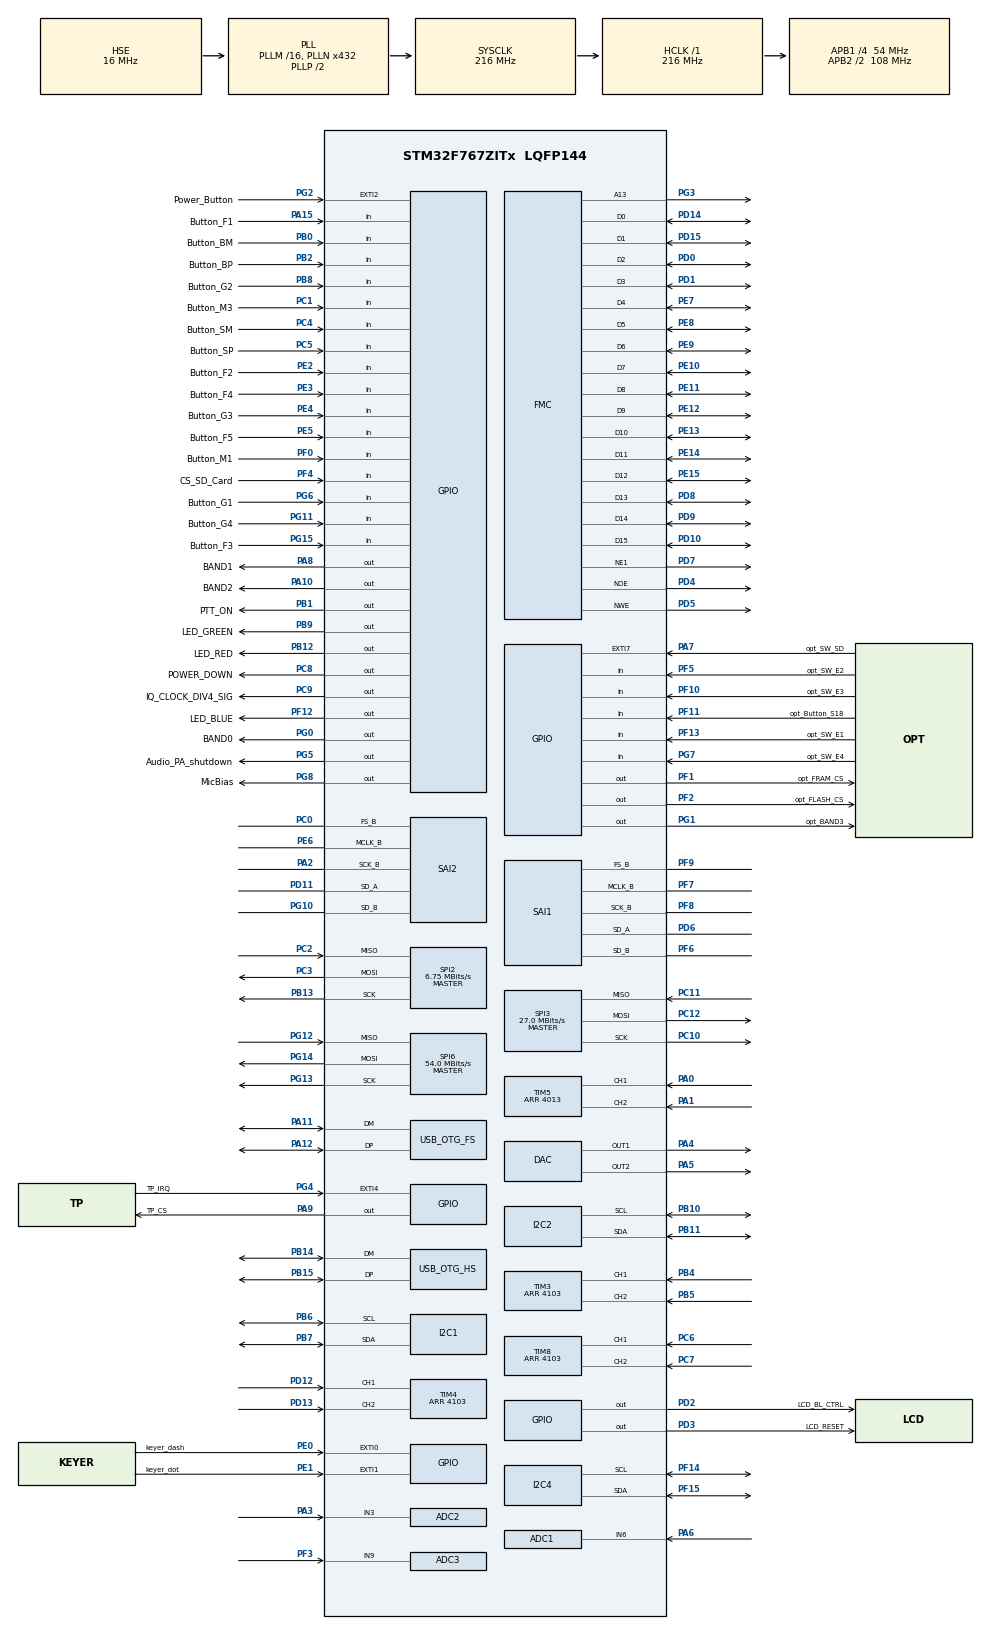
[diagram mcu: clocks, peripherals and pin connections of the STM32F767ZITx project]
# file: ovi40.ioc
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ADC1.Channel-0\#ChannelRegularConversion=ADC_CHANNEL_6
ADC1.ClockPrescaler=ADC_CLOCK_SYNC_PCLK_DIV8
ADC1.ContinuousConvMode=ENABLE
ADC1.EOCSelection=ADC_EOC_SEQ_CONV
ADC1.NbrOfConversionFlag=1
ADC1.Rank-0\#ChannelRegularConversion=1
ADC1.SamplingTime-0\#ChannelRegularConversion=ADC_SAMPLETIME_3CYCLES
ADC1.master=1
ADC2.Channel-0\#ChannelRegularConversion=ADC_CHANNEL_3
ADC2.ClockPrescaler=ADC_CLOCK_SYNC_PCLK_DIV8
ADC2.ContinuousConvMode=ENABLE
ADC2.EOCSelection=ADC_EOC_SEQ_CONV
ADC2.NbrOfConversionFlag=1
ADC2.Rank-0\#ChannelRegularConversion=1
ADC2.SamplingTime-0\#ChannelRegularConversion=ADC_SAMPLETIME_3CYCLES
ADC3.Channel-0\#ChannelRegularConversion=ADC_CHANNEL_9
ADC3.ClockPrescaler=ADC_CLOCK_SYNC_PCLK_DIV8
ADC3.ContinuousConvMode=ENABLE
ADC3.EOCSelection=ADC_EOC_SEQ_CONV
ADC3.NbrOfConversionFlag=1
ADC3.Rank-0\#ChannelRegularConversion=1
ADC3.SamplingTime-0\#ChannelRegularConversion=ADC_SAMPLETIME_3CYCLES
CORTEX_M7.AccessPermission-Cortex_Memory_Protection_Unit_Region0_Settings=MPU_REGION_FULL_ACCESS
CORTEX_M7.BaseAddress-Cortex_Memory_Protection_Unit_Region0_Settings=0x60000000
CORTEX_M7.CPU_DCache=Enabled
CORTEX_M7.CPU_ICache=Enabled
CORTEX_M7.DisableExec-Cortex_Memory_Protection_Unit_Region0_Settings=MPU_INSTRUCTION_ACCESS_DISABLE
CORTEX_M7.Enable-Cortex_Memory_Protection_Unit_Region0_Settings=MPU_REGION_ENABLE
CORTEX_M7.IsShareable-Cortex_Memory_Protection_Unit_Region0_Settings=MPU_ACCESS_SHAREABLE
CORTEX_M7.MPU_Control=MPU_PRIVILEGED_DEFAULT
CORTEX_M7.PREFETCH_ENABLE=0
CORTEX_M7.Size-Cortex_Memory_Protection_Unit_Region0_Settings=MPU_REGION_SIZE_4MB
Dma.Request0=SAI1_A
Dma.Request1=SAI1_B
Dma.Request2=SAI2_A
Dma.Request3=SAI2_B
Dma.Request4=SPI2_TX
Dma.SAI1_A.0.Direction=DMA_PERIPH_TO_MEMORY
Dma.SAI1_A.0.FIFOMode=DMA_FIFOMODE_ENABLE
Dma.SAI1_A.0.FIFOThreshold=DMA_FIFO_THRESHOLD_FULL
Dma.SAI1_A.0.Instance=DMA2_Stream1
Dma.SAI1_A.0.MemBurst=DMA_MBURST_SINGLE
Dma.SAI1_A.0.MemDataAlignment=DMA_MDATAALIGN_HALFWORD
Dma.SAI1_A.0.MemInc=DMA_MINC_ENABLE
Dma.SAI1_A.0.Mode=DMA_CIRCULAR
Dma.SAI1_A.0.PeriphBurst=DMA_PBURST_SINGLE
Dma.SAI1_A.0.PeriphDataAlignment=DMA_PDATAALIGN_HALFWORD
Dma.SAI1_A.0.PeriphInc=DMA_PINC_DISABLE
Dma.SAI1_A.0.Priority=DMA_PRIORITY_HIGH
Dma.SAI1_B.1.Direction=DMA_MEMORY_TO_PERIPH
Dma.SAI1_B.1.FIFOMode=DMA_FIFOMODE_ENABLE
Dma.SAI1_B.1.FIFOThreshold=DMA_FIFO_THRESHOLD_FULL
Dma.SAI1_B.1.Instance=DMA2_Stream0
Dma.SAI1_B.1.MemBurst=DMA_MBURST_SINGLE
Dma.SAI1_B.1.MemDataAlignment=DMA_MDATAALIGN_HALFWORD
Dma.SAI1_B.1.MemInc=DMA_MINC_ENABLE
Dma.SAI1_B.1.Mode=DMA_CIRCULAR
Dma.SAI1_B.1.PeriphBurst=DMA_PBURST_SINGLE
Dma.SAI1_B.1.PeriphDataAlignment=DMA_PDATAALIGN_HALFWORD
Dma.SAI1_B.1.PeriphInc=DMA_PINC_DISABLE
Dma.SAI1_B.1.Priority=DMA_PRIORITY_HIGH
Dma.SAI2_A.2.Direction=DMA_PERIPH_TO_MEMORY
Dma.SAI2_A.2.FIFOMode=DMA_FIFOMODE_ENABLE
Dma.SAI2_A.2.FIFOThreshold=DMA_FIFO_THRESHOLD_FULL
Dma.SAI2_A.2.Instance=DMA2_Stream2
Dma.SAI2_A.2.MemBurst=DMA_MBURST_SINGLE
Dma.SAI2_A.2.MemDataAlignment=DMA_MDATAALIGN_HALFWORD
Dma.SAI2_A.2.MemInc=DMA_MINC_ENABLE
Dma.SAI2_A.2.Mode=DMA_CIRCULAR
Dma.SAI2_A.2.PeriphBurst=DMA_PBURST_SINGLE
Dma.SAI2_A.2.PeriphDataAlignment=DMA_PDATAALIGN_HALFWORD
Dma.SAI2_A.2.PeriphInc=DMA_PINC_DISABLE
Dma.SAI2_A.2.Priority=DMA_PRIORITY_LOW
Dma.SAI2_B.3.Direction=DMA_MEMORY_TO_PERIPH
Dma.SAI2_B.3.FIFOMode=DMA_FIFOMODE_ENABLE
Dma.SAI2_B.3.FIFOThreshold=DMA_FIFO_THRESHOLD_FULL
Dma.SAI2_B.3.Instance=DMA2_Stream6
Dma.SAI2_B.3.MemBurst=DMA_MBURST_SINGLE
Dma.SAI2_B.3.MemDataAlignment=DMA_MDATAALIGN_HALFWORD
Dma.SAI2_B.3.MemInc=DMA_MINC_ENABLE
Dma.SAI2_B.3.Mode=DMA_CIRCULAR
Dma.SAI2_B.3.PeriphBurst=DMA_PBURST_SINGLE
Dma.SAI2_B.3.PeriphDataAlignment=DMA_PDATAALIGN_HALFWORD
Dma.SAI2_B.3.PeriphInc=DMA_PINC_DISABLE
Dma.SAI2_B.3.Priority=DMA_PRIORITY_LOW
Dma.SPI2_TX.4.Direction=DMA_MEMORY_TO_PERIPH
Dma.SPI2_TX.4.FIFOMode=DMA_FIFOMODE_DISABLE
Dma.SPI2_TX.4.Instance=DMA1_Stream4
Dma.SPI2_TX.4.MemDataAlignment=DMA_MDATAALIGN_BYTE
Dma.SPI2_TX.4.MemInc=DMA_MINC_ENABLE
Dma.SPI2_TX.4.Mode=DMA_NORMAL
Dma.SPI2_TX.4.PeriphDataAlignment=DMA_PDATAALIGN_BYTE
Dma.SPI2_TX.4.PeriphInc=DMA_PINC_DISABLE
Dma.SPI2_TX.4.Priority=DMA_PRIORITY_LOW
FMC.DataSetupTime1=15
FMC.WriteFifo1=FMC_WRITE_FIFO_DISABLE
FMC.WriteFifo2=FMC_WRITE_FIFO_DISABLE
FMC.WriteFifo3=FMC_WRITE_FIFO_DISABLE
FMC.WriteFifo4=FMC_WRITE_FIFO_DISABLE
I2C2.Timing=0x20404768
I2C4.Timing=0x20404768
Mcu.Family=STM32F7
Mcu.Name=STM32F767ZITx
Mcu.Package=LQFP144
NVIC.DMA1_Stream4_IRQn=true\:0\:0\:false\:false\:true\:false
NVIC.DMA2_Stream0_IRQn=true\:0\:0\:false\:false\:true\:true
NVIC.DMA2_Stream1_IRQn=true\:0\:0\:false\:false\:true\:true
NVIC.DMA2_Stream2_IRQn=true\:0\:0\:false\:false\:true\:true
NVIC.DMA2_Stream6_IRQn=true\:0\:0\:false\:false\:true\:true
NVIC.EXTI0_IRQn=true\:14\:0\:true\:false\:true\:true
NVIC.EXTI1_IRQn=true\:14\:0\:true\:false\:true\:true
NVIC.OTG_FS_IRQn=true\:1\:0\:true\:false\:true\:true
NVIC.OTG_HS_IRQn=true\:14\:0\:true\:false\:true\:true
NVIC.PriorityGroup=NVIC_PRIORITYGROUP_4
PA0/WKUP.GPIO_PuPd=GPIO_PULLUP
PA0/WKUP.Signal=S_TIM5_CH1
PA1.GPIO_PuPd=GPIO_PULLUP
PA1.Signal=S_TIM5_CH2
PA10.GPIO_Label=BAND2
PA10.PinState=GPIO_PIN_RESET
PA10.Signal=GPIO_Output
PA11.Mode=Device_Only
PA11.Signal=USB_OTG_FS_DM
PA12.Mode=Device_Only
PA12.Signal=USB_OTG_FS_DP
PA13.Mode=Serial_Wire
PA13.Signal=SYS_JTMS-SWDIO
PA14.Mode=Serial_Wire
PA14.Signal=SYS_JTCK-SWCLK
PA15.GPIO_Label=Button_F1
PA15.GPIO_PuPd=GPIO_PULLUP
PA15.Signal=GPIO_Input
PA2.Mode=SAI_B_MasterWithClock
PA2.Signal=SAI2_SCK_B
PA3.Signal=ADCx_IN3
PA4.Signal=COMP_DAC1_group
PA5.Signal=COMP_DAC2_group
PA6.Signal=ADCx_IN6
PA7.GPIO_Label=opt_SW_SD
PA7.GPIO_PuPd=GPIO_PULLUP
PA7.Signal=GPXTI7
PA8.GPIO_Label=BAND1
PA8.Signal=GPIO_Output
PA9.GPIO_Label=TP_CS
PA9.GPIO_Speed=GPIO_SPEED_FREQ_HIGH
PA9.PinState=GPIO_PIN_SET
PA9.Signal=GPIO_Output
PB0.GPIO_Label=Button_BM
PB0.GPIO_PuPd=GPIO_PULLUP
PB0.Signal=GPIO_Input
PB1.GPIO_Label=PTT_ON
PB1.Signal=GPIO_Output
PB10.Mode=I2C
PB10.Signal=I2C2_SCL
PB11.Mode=I2C
PB11.Signal=I2C2_SDA
PB12.GPIO_Label=LED_RED
PB12.Signal=GPIO_Output
PB13.Mode=Full_Duplex_Master
PB13.Signal=SPI2_SCK
PB14.Mode=Host_FS
PB14.Signal=USB_OTG_HS_DM
PB15.Mode=Host_FS
PB15.Signal=USB_OTG_HS_DP
PB2.GPIO_Label=Button_BP
PB2.GPIO_PuPd=GPIO_PULLUP
PB2.Signal=GPIO_Input
PB4.GPIO_PuPd=GPIO_PULLUP
PB4.Signal=S_TIM3_CH1
PB5.GPIO_PuPd=GPIO_PULLUP
PB5.Signal=S_TIM3_CH2
PB6.Mode=I2C
PB6.Signal=I2C1_SCL
PB7.Mode=I2C
PB7.Signal=I2C1_SDA
PB8.GPIO_Label=Button_G2
PB8.GPIO_PuPd=GPIO_PULLUP
PB8.Signal=GPIO_Input
PB9.GPIO_Label=LED_GREEN
PB9.Signal=GPIO_Output
PC0.Mode=SAI_B_MasterWithClock
PC0.Signal=SAI2_FS_B
PC1.GPIO_Label=Button_M3
PC1.GPIO_PuPd=GPIO_PULLUP
PC1.Signal=GPIO_Input
PC10.Mode=Full_Duplex_Master
PC10.Signal=SPI3_SCK
PC11.Mode=Full_Duplex_Master
PC11.Signal=SPI3_MISO
PC12.Mode=Full_Duplex_Master
PC12.Signal=SPI3_MOSI
PC14/OSC32_IN.Mode=LSE-External-Oscillator
PC14/OSC32_IN.Signal=RCC_OSC32_IN
PC15/OSC32_OUT.Mode=LSE-External-Oscillator
PC15/OSC32_OUT.Signal=RCC_OSC32_OUT
PC2.Mode=Full_Duplex_Master
PC2.Signal=SPI2_MISO
PC3.Mode=Full_Duplex_Master
PC3.Signal=SPI2_MOSI
PC4.GPIO_Label=Button_SM
PC4.GPIO_PuPd=GPIO_PULLUP
PC4.Signal=GPIO_Input
PC5.GPIO_Label=Button_SP
PC5.GPIO_PuPd=GPIO_PULLUP
PC5.Signal=GPIO_Input
PC6.GPIO_PuPd=GPIO_PULLUP
PC6.Signal=S_TIM8_CH1
PC7.GPIO_PuPd=GPIO_PULLUP
PC7.Signal=S_TIM8_CH2
PC8.GPIO_Label=POWER_DOWN
PC8.Signal=GPIO_Output
PC9.GPIO_Label=IQ_CLOCK_DIV4_SIG
PC9.Signal=GPIO_Output
PD0.Signal=FMC_D2_DA2
PD1.Signal=FMC_D3_DA3
PD10.Signal=FMC_D15_DA15
PD11.Mode=SAI_A_SyncSlave
PD11.Signal=SAI2_SD_A
PD12.GPIO_PuPd=GPIO_PULLUP
PD12.Signal=S_TIM4_CH1
PD13.GPIO_PuPd=GPIO_PULLUP
PD13.Signal=S_TIM4_CH2
PD14.Signal=FMC_D0_DA0
PD15.Signal=FMC_D1_DA1
PD2.GPIO_Label=LCD_BL_CTRL
PD2.Signal=GPIO_Output
PD3.GPIO_Label=LCD_RESET
PD3.PinState=GPIO_PIN_SET
PD3.Signal=GPIO_Output
PD4.Signal=FMC_NOE
PD5.Signal=FMC_NWE
PD6.Mode=SAI_A_SyncSlave
PD6.Signal=SAI1_SD_A
PD7.Mode=NorPsramChipSelect1_1
PD7.Signal=FMC_NE1
PD8.Signal=FMC_D13_DA13
PD9.Signal=FMC_D14_DA14
PE0.GPIO_Label=keyer_dash
PE0.GPIO_ModeDefaultEXTI=GPIO_MODE_IT_FALLING
PE0.GPIO_PuPd=GPIO_PULLUP
PE0.Signal=GPXTI0
PE1.GPIO_Label=keyer_dot
PE1.GPIO_ModeDefaultEXTI=GPIO_MODE_IT_FALLING
PE1.GPIO_PuPd=GPIO_PULLUP
PE1.Signal=GPXTI1
PE10.Signal=FMC_D7_DA7
PE11.Signal=FMC_D8_DA8
PE12.Signal=FMC_D9_DA9
PE13.Signal=FMC_D10_DA10
PE14.Signal=FMC_D11_DA11
PE15.Signal=FMC_D12_DA12
PE2.GPIO_Label=Button_F2
PE2.GPIO_PuPd=GPIO_PULLUP
PE2.Signal=GPIO_Input
PE3.GPIO_Label=Button_F4
PE3.GPIO_PuPd=GPIO_PULLUP
PE3.Signal=GPIO_Input
PE4.GPIO_Label=Button_G3
PE4.GPIO_PuPd=GPIO_PULLUP
PE4.Signal=GPIO_Input
PE5.GPIO_Label=Button_F5
PE5.GPIO_PuPd=GPIO_PULLUP
PE5.Signal=GPIO_Input
PE6.Mode=SAI_B_MasterWithClock
PE6.Signal=SAI2_MCLK_B
PE7.Signal=FMC_D4_DA4
PE8.Signal=FMC_D5_DA5
PE9.Signal=FMC_D6_DA6
PF0.GPIO_Label=Button_M1
PF0.GPIO_PuPd=GPIO_PULLUP
PF0.Signal=GPIO_Input
PF1.GPIO_Label=opt_FRAM_CS
PF1.Signal=GPIO_Output
PF10.GPIO_Label=opt_SW_E3
PF10.GPIO_PuPd=GPIO_PULLUP
PF10.Signal=GPIO_Input
PF11.GPIO_Label=opt_Button_S18
PF11.GPIO_PuPd=GPIO_PULLUP
PF11.Signal=GPIO_Input
PF12.GPIO_Label=LED_BLUE
PF12.Signal=GPIO_Output
PF13.GPIO_Label=opt_SW_E1
PF13.GPIO_PuPd=GPIO_PULLUP
PF13.Signal=GPIO_Input
PF14.Mode=I2C
PF14.Signal=I2C4_SCL
PF15.Mode=I2C
PF15.Signal=I2C4_SDA
PF2.GPIO_Label=opt_FLASH_CS
PF2.Signal=GPIO_Output
PF3.Mode=IN9
PF3.Signal=ADC3_IN9
PF4.GPIO_Label=CS_SD_Card
PF4.GPIO_PuPd=GPIO_PULLUP
PF4.Signal=GPIO_Input
PF5.GPIO_Label=opt_SW_E2
PF5.GPIO_PuPd=GPIO_PULLUP
PF5.Signal=GPIO_Input
PF6.Mode=SAI_B_MasterWithClock
PF6.Signal=SAI1_SD_B
PF7.Mode=SAI_B_MasterWithClock
PF7.Signal=SAI1_MCLK_B
PF8.Mode=SAI_B_MasterWithClock
PF8.Signal=SAI1_SCK_B
PF9.Mode=SAI_B_MasterWithClock
PF9.Signal=SAI1_FS_B
PG0.GPIO_Label=BAND0
PG0.Signal=GPIO_Output
PG1.GPIO_Label=opt_BAND3
PG1.Signal=GPIO_Output
PG10.Mode=SAI_B_MasterWithClock
PG10.Signal=SAI2_SD_B
PG11.GPIO_Label=Button_G4
PG11.GPIO_PuPd=GPIO_PULLUP
PG11.Signal=GPIO_Input
PG12.Mode=Full_Duplex_Master
PG12.Signal=SPI6_MISO
PG13.Mode=Full_Duplex_Master
PG13.Signal=SPI6_SCK
PG14.Mode=Full_Duplex_Master
PG14.Signal=SPI6_MOSI
PG15.GPIO_Label=Button_F3
PG15.GPIO_PuPd=GPIO_PULLUP
PG15.Signal=GPIO_Input
PG2.GPIO_Label=Power_Button
PG2.GPIO_ModeDefaultEXTI=GPIO_MODE_IT_FALLING
PG2.GPIO_PuPd=GPIO_PULLUP
PG2.Signal=GPXTI2
PG3.Signal=FMC_A13
PG4.GPIO_Label=TP_IRQ
PG4.Signal=GPXTI4
PG5.GPIO_Label=Audio_PA_shutdown
PG5.Signal=GPIO_Output
PG6.GPIO_Label=Button_G1
PG6.GPIO_PuPd=GPIO_PULLUP
PG6.Signal=GPIO_Input
PG7.GPIO_Label=opt_SW_E4
PG7.GPIO_PuPd=GPIO_PULLUP
PG7.Signal=GPIO_Input
PG8.GPIO_Label=MicBias
PG8.Signal=GPIO_Output
PG9.Signal=USART6_RX
PH0/OSC_IN.Mode=HSE-External-Clock-Source
PH0/OSC_IN.Signal=RCC_OSC_IN
PH1/OSC_OUT.Mode=HSE-External-Clock-Source
PH1/OSC_OUT.Signal=RCC_OSC_OUT
ProjectManager.HeapSize=0x200
ProjectManager.StackSize=0x400
ProjectManager.TargetToolchain=Other Toolchains (GPDSC)
RCC.AHBFreq_Value=216000000
RCC.APB1CLKDivider=RCC_HCLK_DIV4
RCC.APB1Freq_Value=54000000
RCC.APB1TimFreq_Value=108000000
RCC.APB2CLKDivider=RCC_HCLK_DIV2
RCC.APB2Freq_Value=108000000
RCC.APB2TimFreq_Value=216000000
RCC.CortexFreq_Value=216000000
RCC.HCLKFreq_Value=216000000
RCC.HSE_VALUE=16000000
RCC.HSI_VALUE=16000000
RCC.I2C1CLockSelection=RCC_I2C1CLKSOURCE_HSI
RCC.PLLI2SN=168
RCC.PLLM=10
RCC.PLLN=270
RCC.PLLQ=9
RCC.PLLSAIQ=5
RCC.PLLSAIQDiv=5
RCC.RCC_MCODiv2=RCC_MCODIV_5
RCC.RTCClockSelection=RCC_RTCCLKSOURCE_LSE
RCC.SYSCLKFreq_VALUE=216000000
RCC.SYSCLKSource=RCC_SYSCLKSOURCE_PLLCLK
RCC.USBFreq_Value=48000000
RCC.VCOOutputFreq_Value=432000000
SAI1.AudioFrequency-SAI_B_MasterWithClock=SAI_AUDIO_FREQUENCY_48K
SAI1.ErrorAudioFreq-SAI_B_MasterWithClock=-0.01 %
SAI1.InitProtocol-SAI_A_SyncSlave=Enable
SAI1.InitProtocol-SAI_B_MasterWithClock=Enable
SAI1.Instance-SAI_A_SyncSlave=SAI$Index_Block_A
SAI1.Instance-SAI_B_MasterWithClock=SAI$Index_Block_B
SAI1.MClockEnable-SAI_B_MasterWithClock=SAI_MASTERCLOCK_ENABLE
SAI1.NoDivider-SAI_B_MasterWithClock=SAI_MASTERDIVIDER_ENABLE
SAI1.RealAudioFreq-SAI_B_MasterWithClock=47.991 KHz
SAI1.Synchro-SAI_A_SyncSlave=SAI_SYNCHRONOUS
SAI1.Synchro-SAI_B_MasterWithClock=SAI_ASYNCHRONOUS
SAI1.VirtualMode-SAI_A_SyncSlave=VM_SLAVE
SAI1.VirtualMode-SAI_B_MasterWithClock=VM_MASTER
SAI1.VirtualProtocol-SAI_A_BASIC=VM_BASIC_PROTOCOL
SAI1.VirtualProtocol-SAI_B_BASIC=VM_BASIC_PROTOCOL
SAI2.AudioFrequency-SAI_B_MasterWithClock=SAI_AUDIO_FREQUENCY_48K
SAI2.ErrorAudioFreq-SAI_B_MasterWithClock=-0.01 %
SAI2.InitProtocol-SAI_A_SyncSlave=Enable
SAI2.InitProtocol-SAI_B_MasterWithClock=Enable
SAI2.Instance-SAI_A_SyncSlave=SAI$Index_Block_A
SAI2.Instance-SAI_B_MasterWithClock=SAI$Index_Block_B
SAI2.MClockEnable-SAI_B_MasterWithClock=SAI_MASTERCLOCK_ENABLE
SAI2.RealAudioFreq-SAI_B_MasterWithClock=47.991 KHz
SAI2.Synchro-SAI_A_SyncSlave=SAI_SYNCHRONOUS
SAI2.Synchro-SAI_B_MasterWithClock=SAI_ASYNCHRONOUS
SAI2.VirtualMode-SAI_A_SyncSlave=VM_SLAVE
SAI2.VirtualMode-SAI_B_MasterWithClock=VM_MASTER
SAI2.VirtualProtocol-SAI_A_BASIC=VM_BASIC_PROTOCOL
SAI2.VirtualProtocol-SAI_B_BASIC=VM_BASIC_PROTOCOL
SH.ADCx_IN3.0=ADC2_IN3,IN3
SH.ADCx_IN6.0=ADC1_IN6,IN6
SH.COMP_DAC1_group.0=DAC_OUT1,DAC_OUT1
SH.COMP_DAC2_group.0=DAC_OUT2,DAC_OUT2
SH.FMC_A13.0=FMC_A13,A13_1
SH.FMC_D0_DA0.0=FMC_D0,16b-d1
SH.FMC_D10_DA10.0=FMC_D10,16b-d1
SH.FMC_D11_DA11.0=FMC_D11,16b-d1
SH.FMC_D12_DA12.0=FMC_D12,16b-d1
SH.FMC_D13_DA13.0=FMC_D13,16b-d1
SH.FMC_D14_DA14.0=FMC_D14,16b-d1
SH.FMC_D15_DA15.0=FMC_D15,16b-d1
SH.FMC_D1_DA1.0=FMC_D1,16b-d1
SH.FMC_D2_DA2.0=FMC_D2,16b-d1
SH.FMC_D3_DA3.0=FMC_D3,16b-d1
SH.FMC_D4_DA4.0=FMC_D4,16b-d1
SH.FMC_D5_DA5.0=FMC_D5,16b-d1
SH.FMC_D6_DA6.0=FMC_D6,16b-d1
SH.FMC_D7_DA7.0=FMC_D7,16b-d1
SH.FMC_D8_DA8.0=FMC_D8,16b-d1
SH.FMC_D9_DA9.0=FMC_D9,16b-d1
SH.FMC_NOE.0=FMC_NOE,Lcd1
SH.FMC_NWE.0=FMC_NWE,Lcd1
SH.S_TIM3_CH1.0=TIM3_CH1,Encoder_Interface
SH.S_TIM3_CH2.0=TIM3_CH2,Encoder_Interface
SH.S_TIM4_CH1.0=TIM4_CH1,Encoder_Interface
SH.S_TIM4_CH2.0=TIM4_CH2,Encoder_Interface
SH.S_TIM5_CH1.0=TIM5_CH1,Encoder_Interface
SH.S_TIM5_CH2.0=TIM5_CH2,Encoder_Interface
SH.S_TIM8_CH1.0=TIM8_CH1,Encoder_Interface
SH.S_TIM8_CH2.0=TIM8_CH2,Encoder_Interface
SPI2.BaudRatePrescaler=SPI_BAUDRATEPRESCALER_8
SPI2.CLKPhase=SPI_PHASE_2EDGE
SPI2.CLKPolarity=SPI_POLARITY_HIGH
SPI2.CalculateBaudRate=6.75 MBits/s
SPI2.DataSize=SPI_DATASIZE_8BIT
SPI2.Direction=SPI_DIRECTION_2LINES
SPI2.Mode=SPI_MODE_MASTER
SPI2.VirtualType=VM_MASTER
SPI3.BaudRatePrescaler=SPI_BAUDRATEPRESCALER_2
SPI3.CalculateBaudRate=27.0 MBits/s
SPI3.Direction=SPI_DIRECTION_2LINES
SPI3.Mode=SPI_MODE_MASTER
SPI3.VirtualType=VM_MASTER
SPI6.BaudRatePrescaler=SPI_BAUDRATEPRESCALER_2
SPI6.CalculateBaudRate=54.0 MBits/s
SPI6.Direction=SPI_DIRECTION_2LINES
SPI6.Mode=SPI_MODE_MASTER
SPI6.VirtualType=VM_MASTER
TIM3.EncoderMode=TIM_ENCODERMODE_TI12
TIM3.IC1Polarity=TIM_ICPOLARITY_FALLING
TIM3.IC2Polarity=TIM_ICPOLARITY_FALLING
TIM3.Period=4103
TIM4.EncoderMode=TIM_ENCODERMODE_TI12
TIM4.IC1Polarity=TIM_ICPOLARITY_FALLING
TIM4.IC2Polarity=TIM_ICPOLARITY_FALLING
TIM4.Period=4103
TIM5.EncoderMode=TIM_ENCODERMODE_TI12
TIM5.IC1Polarity=TIM_ICPOLARITY_FALLING
TIM5.IC2Polarity=TIM_ICPOLARITY_FALLING
TIM5.Period=4013
TIM8.EncoderMode=TIM_ENCODERMODE_TI12
TIM8.IC1Polarity=TIM_ICPOLARITY_FALLING
TIM8.IC2Polarity=TIM_ICPOLARITY_FALLING
TIM8.Period=4103
USB_DEVICE.CLASS_NAME_FS=AUDIO
USB_DEVICE.USBD_AUDIO_FREQ-AUDIO_FS=48000
USB_DEVICE.USBD_LPM_ENABLED-AUDIO_FS=1
USB_DEVICE.USBD_MAX_NUM_INTERFACES-AUDIO_FS=5
USB_DEVICE.VirtualMode-AUDIO_FS=Audio
USB_DEVICE.VirtualModeFS=Audio_FS
USB_HOST.USBH_HandleTypeDef-MSC_HS=hUsbHostHS
USB_HOST.USBH_MAX_NUM_ENDPOINTS-MSC_HS=5
USB_HOST.USBH_MAX_NUM_INTERFACES-MSC_HS=10
USB_HOST.USBH_MAX_NUM_SUPPORTED_CLASS-MSC_HS=5
USB_HOST.VirtualModeHS=Msc
USB_OTG_FS.Sof_enable=ENABLE
USB_OTG_FS.VirtualMode=Device_Only
USB_OTG_FS.lpm_enable=ENABLE
USB_OTG_FS.vbus_sensing_enable=DISABLE
USB_OTG_HS.VirtualMode-Host_FS=Host_FS
VP_FATFS_VS_USB.Mode=USB
VP_RTC_VS_RTC_Activate.Mode=RTC_Enabled
VP_RTC_VS_RTC_Calendar.Mode=RTC_Calendar
VP_SAI1_VP_$IpInstance_SAIA_SAI_BASIC.Mode=SAI_A_BASIC
VP_SAI1_VP_$IpInstance_SAIB_SAI_BASIC.Mode=SAI_B_BASIC
VP_SAI2_VP_$IpInstance_SAIA_SAI_BASIC.Mode=SAI_A_BASIC
VP_SAI2_VP_$IpInstance_SAIB_SAI_BASIC.Mode=SAI_B_BASIC
VP_USB_DEVICE_VS_USB_DEVICE_AUDIO_FS.Mode=AUDIO_FS
VP_USB_HOST_VS_USB_HOST_MSC_HS.Mode=MSC_HS
board=ovi40

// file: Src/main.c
/**
  ******************************************************************************
  * File Name          : main.c
  * Description        : Main program body
  ******************************************************************************
  * This notice applies to any and all portions of this file
  * that are not between comment pairs USER CODE BEGIN and
  * USER CODE END. Other portions of this file, whether
  * inserted by the user or by software development tools
  * are owned by their respective copyright owners.
  *
  * Copyright (c) 2017 STMicroelectronics International N.V.
  * All rights reserved.
  *
  * Redistribution and use in source and binary forms, with or without
  * modification, are permitted, provided that the following conditions are met:
  *
  * 1. Redistribution of source code must retain the above copyright notice,
  *    this list of conditions and the following disclaimer.
  * 2. Redistributions in binary form must reproduce the above copyright notice,
  *    this list of conditions and the following disclaimer in the documentation
  *    and/or other materials provided with the distribution.
  * 3. Neither the name of STMicroelectronics nor the names of other
  *    contributors to this software may be used to endorse or promote products
  *    derived from this software without specific written permission.
  * 4. This software, including modifications and/or derivative works of this
  *    software, must execute solely and exclusively on microcontroller or
  *    microprocessor devices manufactured by or for STMicroelectronics.
  * 5. Redistribution and use of this software other than as permitted under
  *    this license is void and will automatically terminate your rights under
  *    this license.
  *
  * THIS SOFTWARE IS PROVIDED BY STMICROELECTRONICS AND CONTRIBUTORS "AS IS"
  * AND ANY EXPRESS, IMPLIED OR STATUTORY WARRANTIES, INCLUDING, BUT NOT
  * LIMITED TO, THE IMPLIED WARRANTIES OF MERCHANTABILITY, FITNESS FOR A
  * PARTICULAR PURPOSE AND NON-INFRINGEMENT OF THIRD PARTY INTELLECTUAL PROPERTY
  * RIGHTS ARE DISCLAIMED TO THE FULLEST EXTENT PERMITTED BY LAW. IN NO EVENT
  * SHALL STMICROELECTRONICS OR CONTRIBUTORS BE LIABLE FOR ANY DIRECT, INDIRECT,
  * INCIDENTAL, SPECIAL, EXEMPLARY, OR CONSEQUENTIAL DAMAGES (INCLUDING, BUT NOT
  * LIMITED TO, PROCUREMENT OF SUBSTITUTE GOODS OR SERVICES; LOSS OF USE, DATA,
  * OR PROFITS; OR BUSINESS INTERRUPTION) HOWEVER CAUSED AND ON ANY THEORY OF
  * LIABILITY, WHETHER IN CONTRACT, STRICT LIABILITY, OR TORT (INCLUDING
  * NEGLIGENCE OR OTHERWISE) ARISING IN ANY WAY OUT OF THE USE OF THIS SOFTWARE,
  * EVEN IF ADVISED OF THE POSSIBILITY OF SUCH DAMAGE.
  *
  ******************************************************************************
  */
#include "main.h"
#include "stm32f7xx_hal.h"
#include "adc.h"
#include "dac.h"
#include "dma.h"
#include "fatfs.h"
#include "i2c.h"
#include "rtc.h"
#include "sai.h"
#include "spi.h"
#include "tim.h"
#include "usb_device.h"
#include "usb_host.h"
#include "gpio.h"
#include "fmc.h"

/* USER CODE BEGIN PV */
/* Private variables ---------------------------------------------------------*/

/* USER CODE END PV */

void SystemClock_Config(void);
void Error_Handler(void);
static void MPU_Config(void);

/* USER CODE BEGIN PFP */
/* Private function prototypes -----------------------------------------------*/

/* USER CODE END PFP */

/* USER CODE BEGIN 0 */
#ifdef BOOTLOADER_BUILD
void MX_USB_HOST_Process(void);
#include "bootloader/bootloader_main.h"
#else

#include "uhsdr_main.h"

#endif
/* USER CODE END 0 */

int main(void)
{
  /* USER CODE BEGIN 1 */
#ifdef BOOTLOADER_BUILD
  Bootloader_CheckAndGoForBootTarget();
  //  we need to do this as early as possible
#endif
  /* USER CODE END 1 */

  /* MPU Configuration----------------------------------------------------------*/
  MPU_Config();

  /* Enable I-Cache-------------------------------------------------------------*/
  SCB_EnableICache();

#ifndef BOOTLOADER_BUILD
  if ((SCB->CCR & (uint32_t)SCB_CCR_DC_Msk) == 0)  /* enable D-Cache if not active */
  {
      // Reenabling an already enabled DCache is a very bad idea it turns out, as it may cause data corruption
      /* Enable D-Cache-------------------------------------------------------------*/
     SCB_EnableDCache();
  }
#endif

  /* MCU Configuration----------------------------------------------------------*/

  /* Reset of all peripherals, Initializes the Flash interface and the Systick. */
  HAL_Init();

  /* Ensure we have a clock configuration as in reset state, i.e. PLL clock is off and we are using HSI */
  HAL_RCC_DeInit();

  /* Configure the system clock */
  SystemClock_Config();

#ifdef BOOTLOADER_BUILD
  Bootloader_Main();
#else
  /* Initialize all configured peripherals */
  MX_GPIO_Init();
  MX_DMA_Init();
  MX_ADC1_Init();
  MX_ADC2_Init();
  MX_ADC3_Init();
  MX_DAC_Init();
  MX_FMC_Init();
  MX_I2C1_Init();
  MX_I2C2_Init();
  MX_I2C4_Init();
  MX_RTC_Init();
  MX_SAI1_Init();
  MX_SAI2_Init();
  MX_SPI2_Init();
  MX_SPI3_Init();
  MX_SPI6_Init();
  MX_TIM4_Init();
  MX_TIM5_Init();
  MX_TIM8_Init();
  MX_TIM3_Init();
  // MX_USB_HOST_Init();
  // MX_FATFS_Init();
  MX_USB_DEVICE_Init();
#endif

  /* USER CODE BEGIN 2 */
#if defined(USE_USBHOST) || defined(BOOTLOADER_BUILD)
  MX_USB_HOST_Init();

	#if defined(USE_USBDRIVE) || defined(BOOTLOADER_BUILD)
  	  MX_FATFS_Init();
	#endif
#endif

#ifndef BOOTLOADER_BUILD
   mchfMain();
  /* USER CODE END 2 */

  /* Infinite loop */
  /* USER CODE BEGIN WHILE */
#else

  /* USER CODE END 2 */

  /* Infinite loop */
  /* USER CODE BEGIN WHILE */
  while (1)
  {
  /* USER CODE END WHILE */
    MX_USB_HOST_Process();

  /* USER CODE BEGIN 3 */
    Bootloader_UsbHostApplication();

  }
#endif
  /* USER CODE END 3 */

}

/** System Clock Configuration
*/
void SystemClock_Config(void)
{

  RCC_OscInitTypeDef RCC_OscInitStruct;
  RCC_ClkInitTypeDef RCC_ClkInitStruct;
  RCC_PeriphCLKInitTypeDef PeriphClkInitStruct;

    /**Configure LSE Drive Capability
    */
  __HAL_RCC_LSEDRIVE_CONFIG(RCC_LSEDRIVE_MEDIUMLOW);

    /**Configure the main internal regulator output voltage
    */
  __HAL_RCC_PWR_CLK_ENABLE();

  __HAL_PWR_VOLTAGESCALING_CONFIG(PWR_REGULATOR_VOLTAGE_SCALE1);

    /**Initializes the CPU, AHB and APB busses clocks
    */
  RCC_OscInitStruct.OscillatorType = RCC_OSCILLATORTYPE_HSI|RCC_OSCILLATORTYPE_HSE
                              |RCC_OSCILLATORTYPE_LSE;
  RCC_OscInitStruct.HSEState = RCC_HSE_BYPASS;
  RCC_OscInitStruct.LSEState = RCC_LSE_ON;
  RCC_OscInitStruct.HSIState = RCC_HSI_ON;
  RCC_OscInitStruct.HSICalibrationValue = 16;
  RCC_OscInitStruct.PLL.PLLState = RCC_PLL_ON;
  RCC_OscInitStruct.PLL.PLLSource = RCC_PLLSOURCE_HSE;
  RCC_OscInitStruct.PLL.PLLM = 16; //10;
  RCC_OscInitStruct.PLL.PLLN = 432; //270;
  RCC_OscInitStruct.PLL.PLLP = RCC_PLLP_DIV2;
  RCC_OscInitStruct.PLL.PLLQ = 9;
  RCC_OscInitStruct.PLL.PLLR = 2; // we have to set this to keep an assert in HAL_RCC_OscConfig from failing
  if (HAL_RCC_OscConfig(&RCC_OscInitStruct) != HAL_OK)
  {
    Error_Handler();
  }

    /**Activate the Over-Drive mode
    */
  if (HAL_PWREx_EnableOverDrive() != HAL_OK)
  {
    Error_Handler();
  }

    /**Initializes the CPU, AHB and APB busses clocks
    */
  RCC_ClkInitStruct.ClockType = RCC_CLOCKTYPE_HCLK|RCC_CLOCKTYPE_SYSCLK
                              |RCC_CLOCKTYPE_PCLK1|RCC_CLOCKTYPE_PCLK2;
  RCC_ClkInitStruct.SYSCLKSource = RCC_SYSCLKSOURCE_PLLCLK;
  RCC_ClkInitStruct.AHBCLKDivider = RCC_SYSCLK_DIV1;
  RCC_ClkInitStruct.APB1CLKDivider = RCC_HCLK_DIV4;
  RCC_ClkInitStruct.APB2CLKDivider = RCC_HCLK_DIV2;

  if (HAL_RCC_ClockConfig(&RCC_ClkInitStruct, FLASH_LATENCY_7) != HAL_OK)
  {
    Error_Handler();
  }

  PeriphClkInitStruct.PeriphClockSelection = RCC_PERIPHCLK_RTC|RCC_PERIPHCLK_SAI1
                              |RCC_PERIPHCLK_SAI2|RCC_PERIPHCLK_I2C1
                              |RCC_PERIPHCLK_I2C2|RCC_PERIPHCLK_I2C4
                              |RCC_PERIPHCLK_CLK48;
  PeriphClkInitStruct.PLLSAI.PLLSAIN = 344; // 258; //192;
  PeriphClkInitStruct.PLLSAI.PLLSAIR = 2;
  PeriphClkInitStruct.PLLSAI.PLLSAIQ = 7; // 7; //5;
  PeriphClkInitStruct.PLLSAI.PLLSAIP = RCC_PLLSAIP_DIV2;
  PeriphClkInitStruct.PLLSAIDivQ = 2; // 3; //5;
  PeriphClkInitStruct.PLLSAIDivR = RCC_PLLSAIDIVR_2;
  PeriphClkInitStruct.RTCClockSelection = RCC_RTCCLKSOURCE_LSE;
  PeriphClkInitStruct.Sai1ClockSelection = RCC_SAI1CLKSOURCE_PLLSAI;
  PeriphClkInitStruct.Sai2ClockSelection = RCC_SAI2CLKSOURCE_PLLSAI;
  PeriphClkInitStruct.I2c1ClockSelection = RCC_I2C1CLKSOURCE_HSI;
  PeriphClkInitStruct.I2c2ClockSelection = RCC_I2C2CLKSOURCE_PCLK1;
  PeriphClkInitStruct.I2c4ClockSelection = RCC_I2C4CLKSOURCE_PCLK1;
  PeriphClkInitStruct.Clk48ClockSelection = RCC_CLK48SOURCE_PLL;
  if (HAL_RCCEx_PeriphCLKConfig(&PeriphClkInitStruct) != HAL_OK)
  {
    Error_Handler();
  }

    /**Configure the Systick interrupt time
    */
  HAL_SYSTICK_Config(HAL_RCC_GetHCLKFreq()/1000);

    /**Configure the Systick
    */
  HAL_SYSTICK_CLKSourceConfig(SYSTICK_CLKSOURCE_HCLK);

  /* SysTick_IRQn interrupt configuration */
  HAL_NVIC_SetPriority(SysTick_IRQn, 0, 0);
}

/* MPU Configuration */

void MPU_Config(void)
{
  MPU_Region_InitTypeDef MPU_InitStruct;

  /* Disables the MPU */
  HAL_MPU_Disable();
    /**Initializes and configures the Region and the memory to be protected
    */
  MPU_InitStruct.Enable = MPU_REGION_ENABLE;
  MPU_InitStruct.Number = MPU_REGION_NUMBER0;
  MPU_InitStruct.BaseAddress = 0x60000000;
  MPU_InitStruct.Size = MPU_REGION_SIZE_4MB;
  MPU_InitStruct.SubRegionDisable = 0x0;
  MPU_InitStruct.TypeExtField = MPU_TEX_LEVEL0;
  MPU_InitStruct.AccessPermission = MPU_REGION_FULL_ACCESS;
  MPU_InitStruct.DisableExec = MPU_INSTRUCTION_ACCESS_DISABLE;
  MPU_InitStruct.IsShareable = MPU_ACCESS_SHAREABLE;
  MPU_InitStruct.IsCacheable = MPU_ACCESS_NOT_CACHEABLE;
  MPU_InitStruct.IsBufferable = MPU_ACCESS_BUFFERABLE;

  HAL_MPU_ConfigRegion(&MPU_InitStruct);

  /* Enables the MPU */
  HAL_MPU_Enable(MPU_PRIVILEGED_DEFAULT);

}

void Error_Handler()
{
  while(1)
  {
  }
}

#ifdef USE_FULL_ASSERT

/**
   * @brief Reports the name of the source file and the source line number
   * where the assert_param error has occurred.
   * @param file: pointer to the source file name
   * @param line: assert_param error line source number
   * @retval None
   */
void assert_failed(uint8_t* file, uint32_t line)
{
  /* USER CODE BEGIN 6 */
  /* User can add his own implementation to report the file name and line number,
    ex: printf("Wrong parameters value: file %s on line %d\r\n", file, line) */
    for(;;); // We stuck here as long as we do not have any debug interface...
  /* USER CODE END 6 */

}

#endif

/************************ (C) COPYRIGHT STMicroelectronics *****END OF FILE****/
